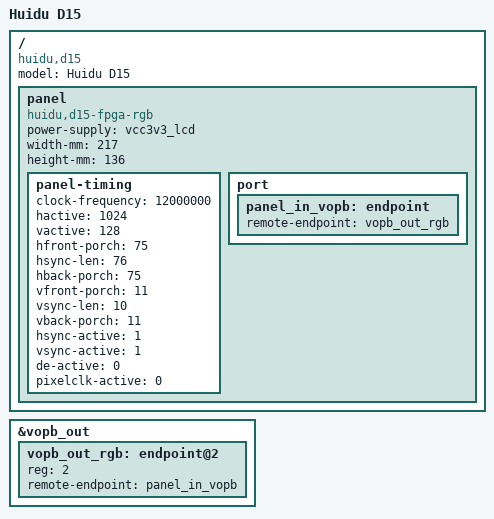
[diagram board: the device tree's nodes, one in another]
// SPDX-License-Identifier: (GPL-2.0+ OR MIT)
/*
 * Huidu D15 (PX30) - reference board: panel timing copied exactly from the
 * stock D15 DTB (simple-panel node, BSP 4.4.159).
 */

/dts-v1/;
#include "px30-huidu.dtsi"

/ {
	model = "Huidu D15";
	compatible = "huidu,d15", "rockchip,px30";

	/*
	 * The "panel" is the LED FPGA's parallel RGB888 input.
	 * Stock: compatible "simple-panel", bus-format 0x1013
	 * (MEDIA_BUS_FMT_BGR888_1X24), rgb-mode "p888", 20 ms
	 * prepare/enable/disable/unprepare delays (not expressible with
	 * panel-dpi; mainline rockchip_rgb always drives P888 for 24-bit).
	 */
	panel: panel {
		compatible = "huidu,d15-fpga-rgb", "panel-dpi";
		power-supply = <&vcc3v3_lcd>;
		width-mm = <217>;
		height-mm = <136>;

		/* 1024x128, htotal 1250, vtotal 160 -> 60 Hz */
		panel-timing {
			clock-frequency = <12000000>;
			hactive = <1024>;
			vactive = <128>;
			hfront-porch = <75>;
			hsync-len = <76>;
			hback-porch = <75>;
			vfront-porch = <11>;
			vsync-len = <10>;
			vback-porch = <11>;
			hsync-active = <1>;
			vsync-active = <1>;
			de-active = <0>;
			pixelclk-active = <0>;
		};

		port {
			panel_in_vopb: endpoint {
				remote-endpoint = <&vopb_out_rgb>;
			};
		};
	};
};

/* VOPB (vop@ff460000) feeds the internal RGB output, as stock route-rgb did */
&vopb_out {
	vopb_out_rgb: endpoint@2 {
		reg = <2>;
		remote-endpoint = <&panel_in_vopb>;
	};
};
